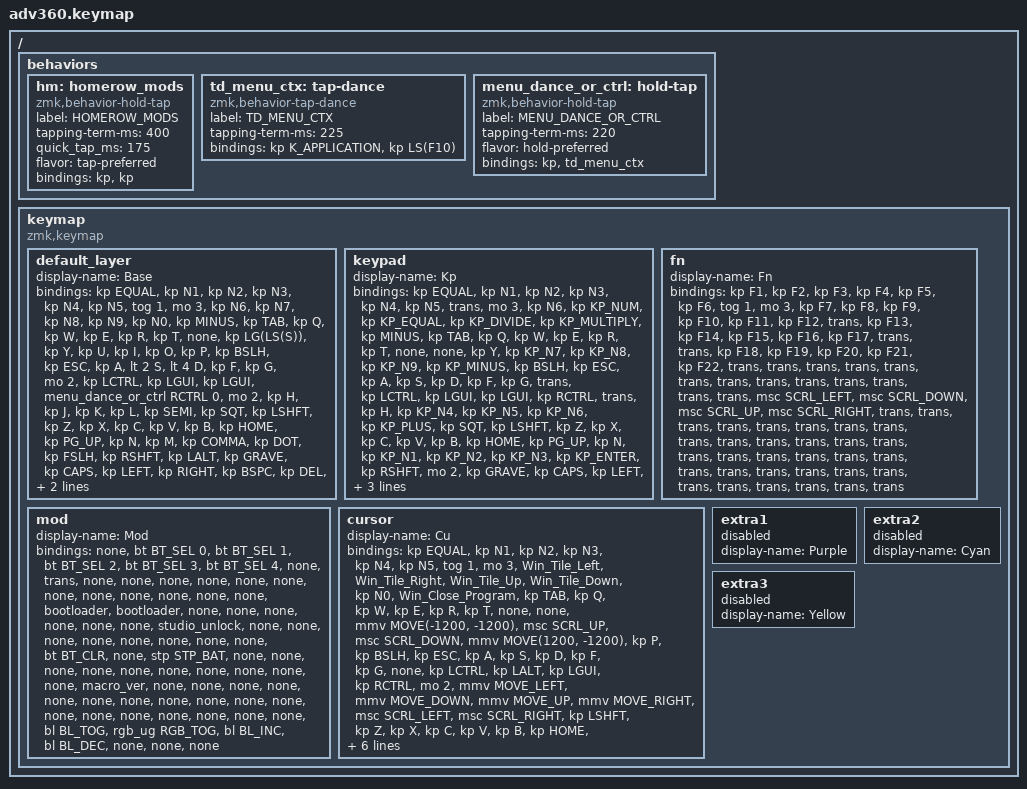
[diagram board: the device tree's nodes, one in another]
#include <behaviors.dtsi>
#include <dt-bindings/zmk/keys.h>
#include <dt-bindings/zmk/bt.h>
#include <dt-bindings/zmk/rgb.h>
#include <dt-bindings/zmk/stp.h>
#include <dt-bindings/zmk/backlight.h>
#define ZMK_POINTING_DEFAULT_MOVE_VAL 1200  // default: 600
#define ZMK_POINTING_DEFAULT_SCRL_VAL 20    // default: 10
#include <dt-bindings/zmk/pointing.h>

/ {
    behaviors {
      #include "macros.dtsi"
      #include "version.dtsi"

      hm: homerow_mods {
          compatible = "zmk,behavior-hold-tap";
          label = "HOMEROW_MODS";
          #binding-cells = <2>;
          tapping-term-ms = <400>;
          quick_tap_ms = <175>;
          flavor = "tap-preferred";
          bindings = <&kp>, <&kp>;
      };


      /*************************************************
      * Recommended: Hold-Tap + Tap-Dance
      * - Hold = Ctrl
      * - Double-tap = Shift+F10
      * - Single-tap = Menu (optional)
      *************************************************/
      td_menu_ctx: tap-dance {
        compatible = "zmk,behavior-tap-dance";
        label = "TD_MENU_CTX";
        #binding-cells = <0>;
        tapping-term-ms = <225>; // adjust for your speed
        bindings = <
          &kp K_APPLICATION   // 1 tap → Menu key (or &none if you want no action)
          &kp LS(F10)         // 2 taps → Shift+F10
        >;
      };
    
    menu_dance_or_ctrl: hold-tap {
        compatible = "zmk,behavior-hold-tap";
        label = "MENU_DANCE_OR_CTRL";
        #binding-cells = <2>;
        tapping-term-ms = <220>;
        flavor = "hold-preferred"; // ensures Ctrl wins during fast chords
        bindings = <
          &kp          // HOLD → Ctrl
          &td_menu_ctx        // TAP → single/double logic
        >;
      };
      
    };

    keymap {
    compatible = "zmk,keymap";

    default_layer {
      display-name = "Base";
      bindings = <
        &kp EQUAL     //EQUAL 
        &kp N1        //N1    
        &kp N2        //N2
        &kp N3        //N3
        &kp N4        //N4
        &kp N5        //N5
        &tog 1        //kp
        
        &mo 3         //Mod
        &kp N6        //N6
        &kp N7        //N7
        &kp N8        //N8
        &kp N9        //N9
        &kp N0        //N0
        &kp MINUS     //MINUS

        //row2
        &kp TAB   
        &kp Q     
        &kp W    
        &kp E    
        &kp R      
        &kp T  
        &none         //(1)
        
        &kp LG(LS(S))  //(3)
        &kp Y  
        &kp U  
        &kp I     
        &kp O    
        &kp P    
        &kp BSLH

        //row3
        &kp ESC   
        &kp A   
        &lt 2 S     // Tap for S, hold for scroll/mouse layer 
        &lt 4 D     // Tap for D, hold for cursor movement
        &kp F      
        &kp G  
        &mo 2       //&tog 2           
        
        &kp LCTRL 
        &kp LGUI    //&mo 2       //&kp LALT  
        &kp LGUI  
        &menu_dance_or_ctrl RCTRL 0
        
        &mo 2       //&tog 2 
        &kp H  
        &kp J  
        &kp K     
        &kp L    
        &kp SEMI 
        &kp SQT
        
        //row4
        &kp LSHFT 
        &kp Z     
        &kp X    
        &kp C    
        &kp V      
        &kp B
        
        &kp HOME 
        &kp PG_UP
        
        &kp N  
        &kp M  
        &kp COMMA 
        &kp DOT  
        &kp FSLH 
        &kp RSHFT

        //row5
        &kp LALT //&mo 2
        &kp GRAVE 
        &kp CAPS 
        &kp LEFT 
        &kp RIGHT
        
        &kp BSPC 
        &kp DEL   
        &kp END  
        &kp PG_DN 
        &kp ENTER 
        &kp SPACE

        &kp DOWN
        &kp UP  
        &kp LBKT 
        &kp RBKT 
        &kp LALT //&mo 2
      >;
    };
    keypad {
      display-name = "Kp";
      bindings = <
        &kp EQUAL 
        &kp N1    
        &kp N2   
        &kp N3   
        &kp N4     
        &kp N5 
        &trans
        
        &mo 3 
        &kp N6 
        &kp KP_NUM 
        &kp KP_EQUAL 
        &kp KP_DIVIDE 
        &kp KP_MULTIPLY 
        &kp MINUS

        //row2
        &kp TAB   
        &kp Q     
        &kp W    
        &kp E    
        &kp R      
        &kp T  
        &none
        
        &none &kp Y  
        &kp KP_N7  
        &kp KP_N8    
        &kp KP_N9     
        &kp KP_MINUS    
        &kp BSLH

        //row 3
        &kp ESC
        &kp A     
        &kp S    
        &kp D    
        &kp F      
        &kp G  
        &trans
        
        &kp LCTRL 
        &kp LGUI 
        &kp LGUI  
        &kp RCTRL
        
        &trans
        &kp H  
        &kp KP_N4  
        &kp KP_N5    
        &kp KP_N6
        &kp KP_PLUS
        &kp SQT
        
        //row 4
        &kp LSHFT 
        &kp Z     
        &kp X    
        &kp C    
        &kp V      
        &kp B
        
        &kp HOME 
        &kp PG_UP
        
        &kp N  
        &kp KP_N1  
        &kp KP_N2    
        &kp KP_N3     
        &kp KP_ENTER    
        &kp RSHFT
        
        //row 5
        &mo 2
        &kp GRAVE
        &kp CAPS
        &kp LEFT 
        &kp RIGHT
        
        &kp BSPC 
        &kp DEL   
        &kp END  
        
        &kp PG_DN 
        &kp ENTER 
        &kp KP_N0
        
        &kp DOWN     
        &kp UP     
        &kp KP_DOT    
        &kp RBKT
        &mo 2
      >;
    };
    fn {
      display-name = "Fn";
      bindings = <
        &kp F1
        &kp F2
        &kp F3
        &kp F4
        &kp F5
        &kp F6
        &tog 1

        &mo 3
        &kp F7
        &kp F8
        &kp F9
        &kp F10
        &kp F11
        &kp F12

        //row2
        &trans    //&kp TAB
        &kp F13  //&kp Q
        &kp F14  //&kp W
        &kp F15  //&kp E
        &kp F16  //&kp R
        &kp F17  //&kp T
        &trans    //&none

        &trans    //&none
        &kp F18    //&mmv_MOVE_UP_LEFT //mmv -10 -10    // Y: top left
        &kp F19    //&mmv_MOVE_UP_RIGHT //&mmv 0 -10     // U: top middle
        &kp F20    //&mmv_MOVE_UP_RIGHT //&mmv 10 -10    // I: top right
        &kp F21    //&kp O
        &kp F22    //&kp P
        &trans    //&kp BSLH

        //row3
        &trans    //&kp ESC
        &trans   //&kp A
        &trans   //&mmv MOVE_LEFT
        &trans   //&mmv MOVE_DOWN
        &trans   //&mmv MOVE_UP
        &trans   //&mmv MOVE_RIGHT
        &trans    //&tog 2

        &trans    //&kp LCTRL
        &trans    //&kp LALT
        &trans    //&kp LGUI
        &trans    //&kp RCTRL

        &trans    //&tog 2
        &msc SCRL_LEFT  //mmv MOVE_X(-400)   // slow mouse left
        &msc SCRL_DOWN  //mmv MOVE_Y(400)    // slow mouse down
        &msc SCRL_UP    //mmv MOVE_Y(-400)   // slow mouse up
        &msc SCRL_RIGHT //mmv MOVE_X(400)    // slow mouse right        
        &trans    //&kp SEMI
        &trans    //&kp SQT

        //row4
        &trans    //&kp LSHFT
        &trans    //&kp Z
        &trans    //&kp X
        &trans    //&kp C
        &trans    //&kp V
        &trans    //&kp B

        &trans    //&kp HOME
        &trans    //&kp PG_UP

        &trans    //&mmv_MOVE_DOWN_LEFT //&mmv -10 10     // N: bottom left
        &trans    //&mmv_MOVE_DOWN_RIGHT //&mmv 0 10      // M: bottom middle
        &trans    //&mmv_MOVE_DOWN_RIGHT //&mmv 10 10     // ,: bottom right
        &trans    //&kp DOT
        &trans    //&kp FSLH
        &trans    //&kp RSHFT

        //row5
        &trans    //&mo 2
        &trans    //&kp GRAVE
        &trans    //&kp CAPS
        &trans    //&kp LEFT
        &trans    //&kp RIGHT

        &trans    //&kp BSPC
        &trans    //&kp DEL
        &trans    //&kp END
        &trans    //&kp PG_DN
        &trans    //&mkp MB1
        &trans    //&mkp MB2

        &trans    //&kp DOWN
        &trans    //&kp UP
        &trans    //&kp LBKT
        &trans    //&kp RBKT
        &trans    //&mo 2
      >;
    };
    mod {
      display-name = "Mod";
      bindings = <
        &none
        &bt BT_SEL 0    //N1
        &bt BT_SEL 1    //N2
        &bt BT_SEL 2    //N3
        &bt BT_SEL 3    //N4
        &bt BT_SEL 4    //N5
        &none           //kp

        &trans          //MOD
        &none           //N6
        &none           //N7
        &none           //N8
        &none           //N9
        &none           //N0
        &none           //Minus

        //row 2
        &none           //
        &none           //
        &none           //
        &none           //
        &none           //
        &none           //
        &bootloader     //(1)

        &bootloader     //(3)
        &none
        &none
        &none
        &none
        &none
        &none

        //row 3
        &studio_unlock
        &none
        &none
        &none
        &none
        &none
        &none

        &none
        &none
        &bt BT_CLR    //RCTRL
        &none
        
        &stp STP_BAT  //(4)
        &none
        &none
        &none
        &none
        &none
        &none

        //row 4
        &none
        &none
        &none
        &none
        &macro_ver            //V
        &none

        &none
        &none
        
        &none
        &none
        &none
        &none
        &none
        &none

        //row 5
        &none
        &none
        &none
        &none
        &none

        &none
        &none
        &none
        &none
        &bl BL_TOG          //ENTER
        &rgb_ug RGB_TOG    //SPACE

        &bl BL_INC        //UP
        &bl BL_DEC        //DOWN
        &none
        &none
        &none
    >;
  };

  cursor {
    display-name = "Cu";
    bindings = <
        &kp EQUAL
        &kp N1
        &kp N2
        &kp N3
        &kp N4
        &kp N5
        &tog 1

        &mo 3
        &Win_Tile_Left        //kp LGUI(LEFT)
        &Win_Tile_Right       //kp LGUI(RIGHT)
        &Win_Tile_Up          //kp LGUI(UP)
        &Win_Tile_Down        //kp LGUI(DOWN)
        &kp N0
        &Win_Close_Program  //&kp MINUS

        //row2
        &kp TAB
        &kp Q
        &kp W
        &kp E
        &kp R
        &kp T
        &none

        &none
        &mmv MOVE(-1200, -1200)  // Y: diagonal up-left
        &msc SCRL_UP             // U: scroll up
        &msc SCRL_DOWN           // I: scroll down
        &mmv MOVE(1200, -1200)   // O: diagonal up-right
        &kp P
        &kp BSLH

        //row3
        &kp ESC
        &kp A
        &kp S
        &kp D
        &kp F
        &kp G
        &none

        &kp LCTRL
        &kp LALT
        &kp LGUI
        &kp RCTRL

        &mo 2
        &mmv MOVE_LEFT
        &mmv MOVE_DOWN
        &mmv MOVE_UP
        &mmv MOVE_RIGHT
        &msc SCRL_LEFT
        &msc SCRL_RIGHT
        
        //row4
        &kp LSHFT
        &kp Z
        &kp X
        &kp C
        &kp V
        &kp B

        &kp HOME
        &kp PG_UP

        &mmv MOVE(-1200, 1200)   // N: diagonal down-left
        &mkp MB3                  // M: middle click
        &mkp MB4                  // <: back button
        &mmv MOVE(1200, 1200)    // >: diagonal down-right
        &mkp MB5                  // /: forward button
        &kp RSHFT

        //row5
        &mo 2
        &kp GRAVE
        &kp CAPS
        &kp LEFT
        &kp RIGHT

        &mkp MB1      //&kp BSPC
        &mkp MB2      //&kp DEL
        &mkp MB3      //&kp END
        &mkp MB3      //&kp PG_DN
        &mkp MB1
        &mkp MB2

        &kp DOWN
        &kp UP
        &kp LBKT
        &kp RBKT
        &mo 2
      >;
    };

    extra1 { 
      display-name = "Purple";    
      status = "reserved";
    };

    extra2 { 
      display-name = "Cyan";    
      status = "reserved";
    };

    extra3 { 
      display-name = "Yellow";    
      status = "reserved";
    };
  };
};

